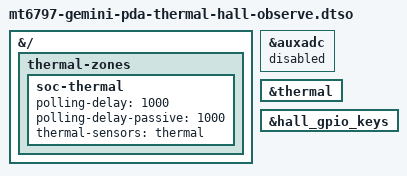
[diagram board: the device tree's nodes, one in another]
// SPDX-License-Identifier: GPL-2.0-only
/*
 * Planet Computers Gemini PDA thermal and Hall switch observation overlay.
 *
 * The vendor MT6797 DT describes the AUXADC at 0x11001000 and thermal
 * controller at 0x1100b000. Mainline has matching MT6797 nodes, a binding,
 * and drivers; the base Gemini DT also supplies the 12-byte thermal
 * calibration cell.
 *
 * The MT6797 thermal driver registers thermal zone 0 through the DT thermal
 * framework.  The provider has #thermal-sensor-cells = <0> and returns the
 * maximum temperature across its six hardware banks, so one SoC observation
 * zone can refer to it without inventing a per-sensor identity.  The vendor
 * driver polls its aggregate CPU temperature every second; retain that
 * observation cadence here.  There are intentionally no trips or cooling
 * maps: the Gemini-specific thresholds and cooling policy have not been
 * validated.
 *
 * The vendor Hall wiring is GPIO66 in GPIO mode with a pull-up. Its driver
 * defines a raw low as FCOVER_CLOSE and reports that as SW_LID, matching the
 * active-low generic gpio-keys definition in the base Gemini DT. The base
 * candidate retains a 64 ms debounce interval; no wake source is requested
 * because suspend/wake behaviour has not been measured.
 *
 * This is deliberately opt-in. It adds no external sensor, regulator,
 * power-domain, or SCP node, and it does not describe a sensor identity.
 */

/dts-v1/;
/plugin/;

&{/} {
	thermal-zones {
		soc-thermal {
			polling-delay = <1000>;
			polling-delay-passive = <1000>;
			thermal-sensors = <&thermal>;
		};
	};
};

&auxadc {
	/* Thermal owns indirect AUXADC sampling and its clock. */
	status = "disabled";
};

&thermal {
	status = "okay";
};

&hall_gpio_keys {
	status = "okay";
};
